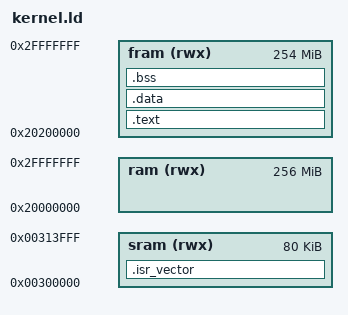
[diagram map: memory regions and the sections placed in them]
/***********************************************************************************/
/* Copyright (c) 2013, Wictor Lund. All rights reserved.			   */
/* Copyright (c) 2013, Åbo Akademi University. All rights reserved.		   */
/* 										   */
/* Redistribution and use in source and binary forms, with or without		   */
/* modification, are permitted provided that the following conditions are met:	   */
/*      * Redistributions of source code must retain the above copyright	   */
/*        notice, this list of conditions and the following disclaimer.		   */
/*      * Redistributions in binary form must reproduce the above copyright	   */
/*        notice, this list of conditions and the following disclaimer in the	   */
/*        documentation and/or other materials provided with the distribution.	   */
/*      * Neither the name of the Åbo Akademi University nor the		   */
/*        names of its contributors may be used to endorse or promote products	   */
/*        derived from this software without specific prior written permission.	   */
/* 										   */
/* THIS SOFTWARE IS PROVIDED BY THE COPYRIGHT HOLDERS AND CONTRIBUTORS "AS IS" AND */
/* ANY EXPRESS OR IMPLIED WARRANTIES, INCLUDING, BUT NOT LIMITED TO, THE IMPLIED   */
/* WARRANTIES OF MERCHANTABILITY AND FITNESS FOR A PARTICULAR PURPOSE ARE	   */
/* DISCLAIMED. IN NO EVENT SHALL ÅBO AKADEMI UNIVERSITY BE LIABLE FOR ANY	   */
/* DIRECT, INDIRECT, INCIDENTAL, SPECIAL, EXEMPLARY, OR CONSEQUENTIAL DAMAGES	   */
/* (INCLUDING, BUT NOT LIMITED TO, PROCUREMENT OF SUBSTITUTE GOODS OR SERVICES;	   */
/* LOSS OF USE, DATA, OR PROFITS; OR BUSINESS INTERRUPTION) HOWEVER CAUSED AND	   */
/* ON ANY THEORY OF LIABILITY, WHETHER IN CONTRACT, STRICT LIABILITY, OR TORT	   */
/* (INCLUDING NEGLIGENCE OR OTHERWISE) ARISING IN ANY WAY OUT OF THE USE OF THIS   */
/* SOFTWARE, EVEN IF ADVISED OF THE POSSIBILITY OF SUCH DAMAGE. 		   */
/***********************************************************************************/

ENTRY(Kernel_Start);

MEMORY
{
	sram (rwx) : ORIGIN = 0x00300000, LENGTH = 0x00014000
	ram  (rwx) : ORIGIN = 0x20000000, LENGTH = 0x10000000
	fram (rwx) : ORIGIN = 0x20200000, LENGTH = (0x10000000 - 0x200000)
}

PROVIDE(__stack_offset = 0x00000);

SECTIONS
{
    .isr_vector :
    {
	_isr_vector_start = .;
	*(.isr_vector*)
	__isr_vector_end = .;
    } > sram

    .text :
    {
        _text = .;
        *(.text*)
        *(.rodata*)
        _etext = .;
    } > fram

    .data : /* AT(ADDR(.text) + SIZEOF(.text)) */
    {
        _data = .;
        *(vtable)
        *(.data*)
        _edata = .;
    } > fram
    .dynamic : { *(.dynamic) }
    .bss :
    {
        _bss = .;
        *(.bss*)
        *(COMMON)
        _ebss = .;
    } > fram
}


